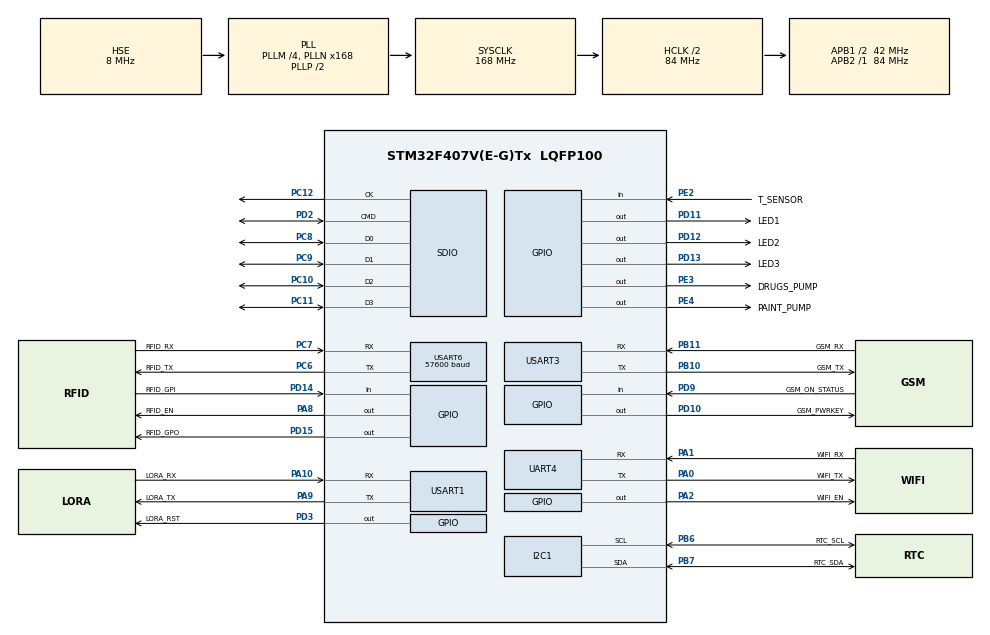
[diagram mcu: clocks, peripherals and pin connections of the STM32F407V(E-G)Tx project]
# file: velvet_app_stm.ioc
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IWDG.Prescaler=IWDG_PRESCALER_256
Mcu.Family=STM32F4
Mcu.Name=STM32F407V(E-G)Tx
Mcu.Package=LQFP100
NVIC.PriorityGroup=NVIC_PRIORITYGROUP_4
PA0-WKUP.GPIO_Label=WIFI_TX
PA0-WKUP.Mode=Asynchronous
PA0-WKUP.Signal=UART4_TX
PA1.GPIO_Label=WIFI_RX
PA1.Mode=Asynchronous
PA1.Signal=UART4_RX
PA10.GPIO_Label=LORA_RX
PA10.Mode=Asynchronous
PA10.Signal=USART1_RX
PA13.Mode=Serial_Wire
PA13.Signal=SYS_JTMS-SWDIO
PA14.Mode=Serial_Wire
PA14.Signal=SYS_JTCK-SWCLK
PA2.GPIO_Label=WIFI_EN
PA2.Signal=GPIO_Output
PA8.GPIO_Label=RFID_EN
PA8.Signal=GPIO_Output
PA9.GPIO_Label=LORA_TX
PA9.Mode=Asynchronous
PA9.Signal=USART1_TX
PB10.GPIO_Label=GSM_TX
PB10.Mode=Asynchronous
PB10.Signal=USART3_TX
PB11.GPIO_Label=GSM_RX
PB11.Mode=Asynchronous
PB11.Signal=USART3_RX
PB3.Signal=SYS_JTDO-SWO
PB6.GPIO_Label=RTC_SCL
PB6.Mode=I2C
PB6.Signal=I2C1_SCL
PB7.GPIO_Label=RTC_SDA
PB7.Mode=I2C
PB7.Signal=I2C1_SDA
PC10.Mode=SD_4_bits_Wide_bus
PC10.Signal=SDIO_D2
PC11.Mode=SD_4_bits_Wide_bus
PC11.Signal=SDIO_D3
PC12.Mode=SD_4_bits_Wide_bus
PC12.Signal=SDIO_CK
PC6.GPIO_Label=RFID_TX
PC6.Mode=Asynchronous
PC6.Signal=USART6_TX
PC7.GPIO_Label=RFID_RX
PC7.Mode=Asynchronous
PC7.Signal=USART6_RX
PC8.Mode=SD_4_bits_Wide_bus
PC8.Signal=SDIO_D0
PC9.Mode=SD_4_bits_Wide_bus
PC9.Signal=SDIO_D1
PD10.GPIO_Label=GSM_PWRKEY
PD10.Signal=GPIO_Output
PD11.GPIO_Label=LED1
PD11.Signal=GPIO_Output
PD12.GPIO_Label=LED2
PD12.Signal=GPIO_Output
PD13.GPIO_Label=LED3
PD13.Signal=GPIO_Output
PD14.GPIO_Label=RFID_GPI
PD14.Signal=GPIO_Input
PD15.GPIO_Label=RFID_GPO
PD15.Signal=GPIO_Output
PD2.Mode=SD_4_bits_Wide_bus
PD2.Signal=SDIO_CMD
PD3.GPIO_Label=LORA_RST
PD3.Signal=GPIO_Output
PD9.GPIO_Label=GSM_ON_STATUS
PD9.Signal=GPIO_Input
PE2.GPIO_Label=T_SENSOR
PE2.Signal=GPIO_Input
PE3.GPIO_Label=DRUGS_PUMP
PE3.Signal=GPIO_Output
PE4.GPIO_Label=PAINT_PUMP
PE4.Signal=GPIO_Output
PH0-OSC_IN.Mode=HSE-External-Oscillator
PH0-OSC_IN.Signal=RCC_OSC_IN
PH1-OSC_OUT.Mode=HSE-External-Oscillator
PH1-OSC_OUT.Signal=RCC_OSC_OUT
ProjectManager.HeapSize=0x2000
ProjectManager.StackSize=0x4000
ProjectManager.TargetToolchain=MDK-ARM V5.32
RCC.48MHZClocksFreq_Value=48000000
RCC.AHBCLKDivider=RCC_SYSCLK_DIV2
RCC.AHBFreq_Value=84000000
RCC.APB1CLKDivider=RCC_HCLK_DIV2
RCC.APB1Freq_Value=42000000
RCC.APB1TimFreq_Value=84000000
RCC.APB2Freq_Value=84000000
RCC.APB2TimFreq_Value=84000000
RCC.CortexFreq_Value=84000000
RCC.HCLKFreq_Value=84000000
RCC.HSE_VALUE=8000000
RCC.HSI_VALUE=16000000
RCC.LSE_VALUE=32768
RCC.PLLM=4
RCC.PLLN=168
RCC.PLLQ=7
RCC.PLLSourceVirtual=RCC_PLLSOURCE_HSE
RCC.SYSCLKFreq_VALUE=168000000
RCC.SYSCLKSource=RCC_SYSCLKSOURCE_PLLCLK
RCC.VCOOutputFreq_Value=336000000
UART4.VirtualMode=Asynchronous
USART1.VirtualMode=VM_ASYNC
USART3.VirtualMode=VM_ASYNC
USART6.BaudRate=57600
USART6.VirtualMode=VM_ASYNC
VP_IWDG_VS_IWDG.Mode=IWDG_Activate
board=custom

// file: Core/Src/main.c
/* USER CODE BEGIN Header */
/**
  ******************************************************************************
  * @file           : main.c
  * @brief          : Main program body
  ******************************************************************************
  * @attention
  *
  * Copyright (c) 2023 STMicroelectronics.
  * All rights reserved.
  *
  * This software is licensed under terms that can be found in the LICENSE file
  * in the root directory of this software component.
  * If no LICENSE file comes with this software, it is provided AS-IS.
  *
  ******************************************************************************
  */
/* USER CODE END Header */
#include "main.h"

/* USER CODE BEGIN Includes */
#include "const.h"
/* USER CODE END Includes */

I2C_HandleTypeDef hi2c1;

IWDG_HandleTypeDef hiwdg;

SD_HandleTypeDef hsd;

UART_HandleTypeDef huart4;
UART_HandleTypeDef huart1;
UART_HandleTypeDef huart3;
UART_HandleTypeDef huart6;

void SystemClock_Config(void);
static void MX_GPIO_Init(void);
static void MX_USART6_UART_Init(void);
static void MX_UART4_Init(void);
static void MX_I2C1_Init(void);
static void MX_SDIO_SD_Init(void);
static void MX_USART1_UART_Init(void);
static void MX_USART3_UART_Init(void);
static void MX_IWDG_Init(void);

int main(void)
{

  /* MCU Configuration--------------------------------------------------------*/

  /* Reset of all peripherals, Initializes the Flash interface and the Systick. */
  HAL_Init();

  /* Configure the system clock */
  SystemClock_Config();

  /* Initialize all configured peripherals */
  MX_GPIO_Init();
  MX_USART6_UART_Init();
  MX_UART4_Init();
  MX_I2C1_Init();
  MX_SDIO_SD_Init();
  MX_USART1_UART_Init();
  MX_USART3_UART_Init();
  MX_IWDG_Init();

  /* Infinite loop */
  while (1)
  {

  }
}

void SystemClock_Config(void)
{
  RCC_OscInitTypeDef RCC_OscInitStruct = {0};
  RCC_ClkInitTypeDef RCC_ClkInitStruct = {0};

  /** Configure the main internal regulator output voltage
  */
  __HAL_RCC_PWR_CLK_ENABLE();
  __HAL_PWR_VOLTAGESCALING_CONFIG(PWR_REGULATOR_VOLTAGE_SCALE1);

  /** Initializes the RCC Oscillators according to the specified parameters
  * in the RCC_OscInitTypeDef structure.
  */
  RCC_OscInitStruct.OscillatorType = RCC_OSCILLATORTYPE_LSI|RCC_OSCILLATORTYPE_HSE;
  RCC_OscInitStruct.HSEState = RCC_HSE_ON;
  RCC_OscInitStruct.LSIState = RCC_LSI_ON;
  RCC_OscInitStruct.PLL.PLLState = RCC_PLL_ON;
  RCC_OscInitStruct.PLL.PLLSource = RCC_PLLSOURCE_HSE;
  RCC_OscInitStruct.PLL.PLLM = 4;
  RCC_OscInitStruct.PLL.PLLN = 168;
  RCC_OscInitStruct.PLL.PLLP = RCC_PLLP_DIV2;
  RCC_OscInitStruct.PLL.PLLQ = 7;
  if (HAL_RCC_OscConfig(&RCC_OscInitStruct) != HAL_OK)
  {
    Error_Handler();
  }

  /** Initializes the CPU, AHB and APB buses clocks
  */
  RCC_ClkInitStruct.ClockType = RCC_CLOCKTYPE_HCLK|RCC_CLOCKTYPE_SYSCLK
                              |RCC_CLOCKTYPE_PCLK1|RCC_CLOCKTYPE_PCLK2;
  RCC_ClkInitStruct.SYSCLKSource = RCC_SYSCLKSOURCE_PLLCLK;
  RCC_ClkInitStruct.AHBCLKDivider = RCC_SYSCLK_DIV2;
  RCC_ClkInitStruct.APB1CLKDivider = RCC_HCLK_DIV2;
  RCC_ClkInitStruct.APB2CLKDivider = RCC_HCLK_DIV1;

  if (HAL_RCC_ClockConfig(&RCC_ClkInitStruct, FLASH_LATENCY_2) != HAL_OK)
  {
    Error_Handler();
  }
}

static void MX_I2C1_Init(void)
{

  hi2c1.Instance = I2C1;
  hi2c1.Init.ClockSpeed = 100000;
  hi2c1.Init.DutyCycle = I2C_DUTYCYCLE_2;
  hi2c1.Init.OwnAddress1 = 0;
  hi2c1.Init.AddressingMode = I2C_ADDRESSINGMODE_7BIT;
  hi2c1.Init.DualAddressMode = I2C_DUALADDRESS_DISABLE;
  hi2c1.Init.OwnAddress2 = 0;
  hi2c1.Init.GeneralCallMode = I2C_GENERALCALL_DISABLE;
  hi2c1.Init.NoStretchMode = I2C_NOSTRETCH_DISABLE;
  if (HAL_I2C_Init(&hi2c1) != HAL_OK)
  {
    Error_Handler();
  }

}

static void MX_IWDG_Init(void)
{

  hiwdg.Instance = IWDG;
  hiwdg.Init.Prescaler = IWDG_PRESCALER_256;
  hiwdg.Init.Reload = 4095;
  if (HAL_IWDG_Init(&hiwdg) != HAL_OK)
  {
    Error_Handler();
  }

}

static void MX_SDIO_SD_Init(void)
{

  hsd.Instance = SDIO;
  hsd.Init.ClockEdge = SDIO_CLOCK_EDGE_RISING;
  hsd.Init.ClockBypass = SDIO_CLOCK_BYPASS_DISABLE;
  hsd.Init.ClockPowerSave = SDIO_CLOCK_POWER_SAVE_DISABLE;
  hsd.Init.BusWide = SDIO_BUS_WIDE_4B;
  hsd.Init.HardwareFlowControl = SDIO_HARDWARE_FLOW_CONTROL_DISABLE;
  hsd.Init.ClockDiv = 0;
  if (HAL_SD_Init(&hsd) != HAL_OK)
  {
    Error_Handler();
  }
  if (HAL_SD_ConfigWideBusOperation(&hsd, SDIO_BUS_WIDE_4B) != HAL_OK)
  {
    Error_Handler();
  }

}

static void MX_UART4_Init(void)
{

  huart4.Instance = UART4;
  huart4.Init.BaudRate = 115200;
  huart4.Init.WordLength = UART_WORDLENGTH_8B;
  huart4.Init.StopBits = UART_STOPBITS_1;
  huart4.Init.Parity = UART_PARITY_NONE;
  huart4.Init.Mode = UART_MODE_TX_RX;
  huart4.Init.HwFlowCtl = UART_HWCONTROL_NONE;
  huart4.Init.OverSampling = UART_OVERSAMPLING_16;
  if (HAL_UART_Init(&huart4) != HAL_OK)
  {
    Error_Handler();
  }

}

static void MX_USART1_UART_Init(void)
{

  huart1.Instance = USART1;
  huart1.Init.BaudRate = 115200;
  huart1.Init.WordLength = UART_WORDLENGTH_8B;
  huart1.Init.StopBits = UART_STOPBITS_1;
  huart1.Init.Parity = UART_PARITY_NONE;
  huart1.Init.Mode = UART_MODE_TX_RX;
  huart1.Init.HwFlowCtl = UART_HWCONTROL_NONE;
  huart1.Init.OverSampling = UART_OVERSAMPLING_16;
  if (HAL_UART_Init(&huart1) != HAL_OK)
  {
    Error_Handler();
  }

}

static void MX_USART3_UART_Init(void)
{

  huart3.Instance = USART3;
  huart3.Init.BaudRate = 115200;
  huart3.Init.WordLength = UART_WORDLENGTH_8B;
  huart3.Init.StopBits = UART_STOPBITS_1;
  huart3.Init.Parity = UART_PARITY_NONE;
  huart3.Init.Mode = UART_MODE_TX_RX;
  huart3.Init.HwFlowCtl = UART_HWCONTROL_NONE;
  huart3.Init.OverSampling = UART_OVERSAMPLING_16;
  if (HAL_UART_Init(&huart3) != HAL_OK)
  {
    Error_Handler();
  }

}

static void MX_USART6_UART_Init(void)
{

  huart6.Instance = USART6;
  huart6.Init.BaudRate = 57600;
  huart6.Init.WordLength = UART_WORDLENGTH_8B;
  huart6.Init.StopBits = UART_STOPBITS_1;
  huart6.Init.Parity = UART_PARITY_NONE;
  huart6.Init.Mode = UART_MODE_TX_RX;
  huart6.Init.HwFlowCtl = UART_HWCONTROL_NONE;
  huart6.Init.OverSampling = UART_OVERSAMPLING_16;
  if (HAL_UART_Init(&huart6) != HAL_OK)
  {
    Error_Handler();
  }

}

static void MX_GPIO_Init(void)
{
  GPIO_InitTypeDef GPIO_InitStruct = {0};

  /* GPIO Ports Clock Enable */
  __HAL_RCC_GPIOE_CLK_ENABLE();
  __HAL_RCC_GPIOH_CLK_ENABLE();
  __HAL_RCC_GPIOA_CLK_ENABLE();
  __HAL_RCC_GPIOB_CLK_ENABLE();
  __HAL_RCC_GPIOD_CLK_ENABLE();
  __HAL_RCC_GPIOC_CLK_ENABLE();

  /*Configure GPIO pin Output Level */
  HAL_GPIO_WritePin(GPIOE, DRUGS_PUMP_Pin|PAINT_PUMP_Pin, GPIO_PIN_RESET);

  /*Configure GPIO pin Output Level */
  HAL_GPIO_WritePin(GPIOA, WIFI_EN_Pin|RFID_EN_Pin, GPIO_PIN_RESET);

  /*Configure GPIO pin Output Level */
  HAL_GPIO_WritePin(GPIOD, GSM_PWRKEY_Pin|LED1_Pin|LED2_Pin|LED3_Pin
                          |RFID_GPO_Pin|LORA_RST_Pin, GPIO_PIN_RESET);

  /*Configure GPIO pin : T_SENSOR_Pin */
  GPIO_InitStruct.Pin = T_SENSOR_Pin;
  GPIO_InitStruct.Mode = GPIO_MODE_INPUT;
  GPIO_InitStruct.Pull = GPIO_NOPULL;
  HAL_GPIO_Init(T_SENSOR_GPIO_Port, &GPIO_InitStruct);

  /*Configure GPIO pins : DRUGS_PUMP_Pin PAINT_PUMP_Pin */
  GPIO_InitStruct.Pin = DRUGS_PUMP_Pin|PAINT_PUMP_Pin;
  GPIO_InitStruct.Mode = GPIO_MODE_OUTPUT_PP;
  GPIO_InitStruct.Pull = GPIO_NOPULL;
  GPIO_InitStruct.Speed = GPIO_SPEED_FREQ_LOW;
  HAL_GPIO_Init(GPIOE, &GPIO_InitStruct);

  /*Configure GPIO pins : WIFI_EN_Pin RFID_EN_Pin */
  GPIO_InitStruct.Pin = WIFI_EN_Pin|RFID_EN_Pin;
  GPIO_InitStruct.Mode = GPIO_MODE_OUTPUT_PP;
  GPIO_InitStruct.Pull = GPIO_NOPULL;
  GPIO_InitStruct.Speed = GPIO_SPEED_FREQ_LOW;
  HAL_GPIO_Init(GPIOA, &GPIO_InitStruct);

  /*Configure GPIO pins : GSM_ON_STATUS_Pin RFID_GPI_Pin */
  GPIO_InitStruct.Pin = GSM_ON_STATUS_Pin|RFID_GPI_Pin;
  GPIO_InitStruct.Mode = GPIO_MODE_INPUT;
  GPIO_InitStruct.Pull = GPIO_NOPULL;
  HAL_GPIO_Init(GPIOD, &GPIO_InitStruct);

  /*Configure GPIO pins : GSM_PWRKEY_Pin LED1_Pin LED2_Pin LED3_Pin
                           RFID_GPO_Pin LORA_RST_Pin */
  GPIO_InitStruct.Pin = GSM_PWRKEY_Pin|LED1_Pin|LED2_Pin|LED3_Pin
                          |RFID_GPO_Pin|LORA_RST_Pin;
  GPIO_InitStruct.Mode = GPIO_MODE_OUTPUT_PP;
  GPIO_InitStruct.Pull = GPIO_NOPULL;
  GPIO_InitStruct.Speed = GPIO_SPEED_FREQ_LOW;
  HAL_GPIO_Init(GPIOD, &GPIO_InitStruct);

}

void Error_Handler(void)
{
  __disable_irq();
  while (1)
  {
  }
}
